# VPAC0_PAR_VPAC_NF_S_VBUSP_MMR_VBUSP_NF_CFG register map
Vendor: Texas Instruments
Peripheral module from a debugger description file (folder J7ES).
Registers are 32-bit, access per field, reset 0x0 unless marked. A register's access mark holds for its fields unless they carry their own. Offsets are as the file gives them; lines under a group give offsets from that group; [hi:lo] are bit positions; {n}, {i} and the like mark numbered series; 'fields as' and 'values as' point back to an identical list; <NAME> marks a mode.

## VPAC0_PAR_VPAC_NF_S_VBUSP_MMR_VBUSP_NF_CFG
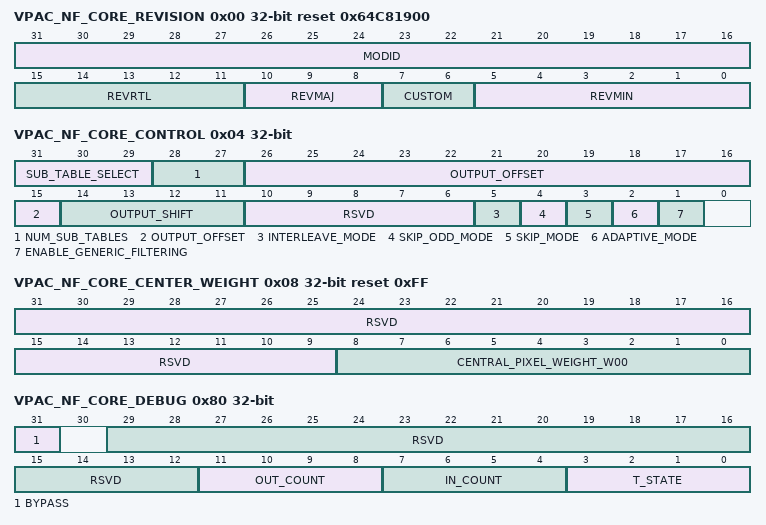
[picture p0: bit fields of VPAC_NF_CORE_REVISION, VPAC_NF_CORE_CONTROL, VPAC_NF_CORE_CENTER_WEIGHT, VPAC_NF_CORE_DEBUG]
0x00 VPAC_NF_CORE_REVISION ro reset 0x64C81900 — The Register contains the major and minor revisions for the module.
  [31:16] MODID — Module ID field
  [15:11] REVRTL — RTL
  [10:8] REVMAJ — Major
  [7:6] CUSTOM
  [5:0] REVMIN — Minor
0x04 VPAC_NF_CORE_CONTROL — This contains parameters to NF Core
  [31:29] SUB_TABLE_SELECT rw — Defines which sub table is used statically.
  [28:27] NUM_SUB_TABLES rw — Defines the number of sub-tables
  [26:15] OUTPUT_OFFSET rw — unsigned offset value to added to output after shifting and before clipping
  [14:11] OUTPUT_SHIFT rw — Signed 4 bit (24 is added before using it inside IP)
  [10:6] RSVD ro — Always read as 0.
  [5] INTERLEAVE_MODE rw
  [4] SKIP_ODD_MODE rw
  [3] SKIP_MODE rw
  [2] ADAPTIVE_MODE rw — Defines what controls the selection of the sub table.
  [1] ENABLE_GENERIC_FILTERING rw — Filter mode,
0x08 VPAC_NF_CORE_CENTER_WEIGHT reset 0xFF — Contain center weight parameter
  [31:9] RSVD ro — Always read as 0.
  [8:0] CENTRAL_PIXEL_WEIGHT_W00 rw — Central pixel weight, 8 bit unsigned in Bi-lateral filtering, 9 bit signed in Generic 2D Filtering
0x80 VPAC_NF_CORE_DEBUG
  [31] BYPASS rw — Bypass Mode When enabled output equals the input , namely C2_R0 input matrix
  [29:12] RSVD ro — Always read as 0.
  [11:8] OUT_COUNT ro — output free running counter , gets reset on start of line
  [7:4] IN_COUNT ro — input free running counter , gets reset on start of line
  [3:0] T_STATE ro — StateMachine State
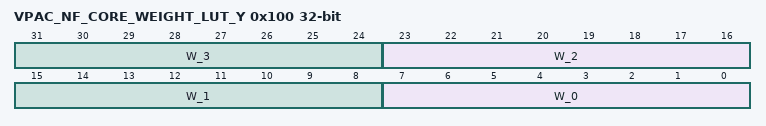
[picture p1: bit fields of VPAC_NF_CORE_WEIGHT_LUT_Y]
0x100 VPAC_NF_CORE_WEIGHT_LUT_Y rw — This contains weights for LUT. These acts as 1280 size LUT (8 bit each) in Bi-lateral mode, while 24 size (9 bit in 16 bit container) in Generic Filtering mode Offset = 001C2100h + (y * 4h); where y = 0h to 13Fh
  [8n+7:8n] W_{n} (n=0..3) — weight W_{n}
